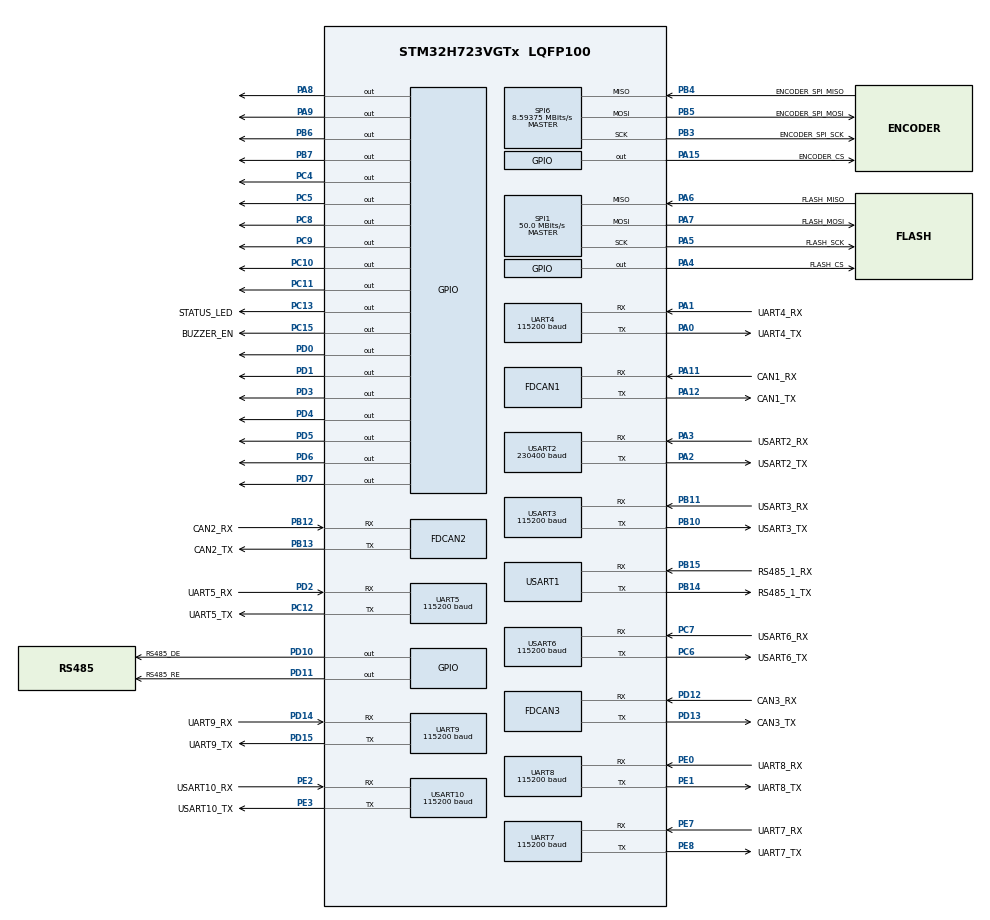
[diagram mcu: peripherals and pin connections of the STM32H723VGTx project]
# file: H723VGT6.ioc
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CORTEX_M7.CPU_DCache=Enabled
CORTEX_M7.CPU_ICache=Enabled
CORTEX_M7.default_mode_Activation=1
Dma.Request0=UART7_RX
Dma.Request1=UART7_TX
Dma.Request10=UART9_RX
Dma.Request2=USART1_RX
Dma.Request3=SPI1_RX
Dma.Request4=SPI1_TX
Dma.Request5=UART5_RX
Dma.Request6=USART6_RX
Dma.Request7=USART2_RX
Dma.Request8=UART8_RX
Dma.Request9=UART4_RX
Dma.SPI1_RX.3.Direction=DMA_PERIPH_TO_MEMORY
Dma.SPI1_RX.3.EventEnable=DISABLE
Dma.SPI1_RX.3.FIFOMode=DMA_FIFOMODE_DISABLE
Dma.SPI1_RX.3.Instance=DMA1_Stream6
Dma.SPI1_RX.3.MemDataAlignment=DMA_MDATAALIGN_BYTE
Dma.SPI1_RX.3.MemInc=DMA_MINC_ENABLE
Dma.SPI1_RX.3.Mode=DMA_NORMAL
Dma.SPI1_RX.3.PeriphDataAlignment=DMA_PDATAALIGN_BYTE
Dma.SPI1_RX.3.PeriphInc=DMA_PINC_DISABLE
Dma.SPI1_RX.3.Polarity=HAL_DMAMUX_REQ_GEN_RISING
Dma.SPI1_RX.3.Priority=DMA_PRIORITY_HIGH
Dma.SPI1_RX.3.RequestNumber=1
Dma.SPI1_RX.3.SignalID=NONE
Dma.SPI1_RX.3.SyncEnable=DISABLE
Dma.SPI1_RX.3.SyncPolarity=HAL_DMAMUX_SYNC_NO_EVENT
Dma.SPI1_RX.3.SyncRequestNumber=1
Dma.SPI1_RX.3.SyncSignalID=NONE
Dma.SPI1_TX.4.Direction=DMA_MEMORY_TO_PERIPH
Dma.SPI1_TX.4.EventEnable=DISABLE
Dma.SPI1_TX.4.FIFOMode=DMA_FIFOMODE_DISABLE
Dma.SPI1_TX.4.Instance=DMA1_Stream7
Dma.SPI1_TX.4.MemDataAlignment=DMA_MDATAALIGN_BYTE
Dma.SPI1_TX.4.MemInc=DMA_MINC_ENABLE
Dma.SPI1_TX.4.Mode=DMA_NORMAL
Dma.SPI1_TX.4.PeriphDataAlignment=DMA_PDATAALIGN_BYTE
Dma.SPI1_TX.4.PeriphInc=DMA_PINC_DISABLE
Dma.SPI1_TX.4.Polarity=HAL_DMAMUX_REQ_GEN_RISING
Dma.SPI1_TX.4.Priority=DMA_PRIORITY_HIGH
Dma.SPI1_TX.4.RequestNumber=1
Dma.SPI1_TX.4.SignalID=NONE
Dma.SPI1_TX.4.SyncEnable=DISABLE
Dma.SPI1_TX.4.SyncPolarity=HAL_DMAMUX_SYNC_NO_EVENT
Dma.SPI1_TX.4.SyncRequestNumber=1
Dma.SPI1_TX.4.SyncSignalID=NONE
Dma.UART4_RX.9.Direction=DMA_PERIPH_TO_MEMORY
Dma.UART4_RX.9.EventEnable=DISABLE
Dma.UART4_RX.9.FIFOMode=DMA_FIFOMODE_DISABLE
Dma.UART4_RX.9.Instance=DMA2_Stream3
Dma.UART4_RX.9.MemDataAlignment=DMA_MDATAALIGN_BYTE
Dma.UART4_RX.9.MemInc=DMA_MINC_ENABLE
Dma.UART4_RX.9.Mode=DMA_CIRCULAR
Dma.UART4_RX.9.PeriphDataAlignment=DMA_PDATAALIGN_BYTE
Dma.UART4_RX.9.PeriphInc=DMA_PINC_DISABLE
Dma.UART4_RX.9.Polarity=HAL_DMAMUX_REQ_GEN_RISING
Dma.UART4_RX.9.Priority=DMA_PRIORITY_VERY_HIGH
Dma.UART4_RX.9.RequestNumber=1
Dma.UART4_RX.9.SignalID=NONE
Dma.UART4_RX.9.SyncEnable=DISABLE
Dma.UART4_RX.9.SyncPolarity=HAL_DMAMUX_SYNC_NO_EVENT
Dma.UART4_RX.9.SyncRequestNumber=1
Dma.UART4_RX.9.SyncSignalID=NONE
Dma.UART5_RX.5.Direction=DMA_PERIPH_TO_MEMORY
Dma.UART5_RX.5.EventEnable=DISABLE
Dma.UART5_RX.5.FIFOMode=DMA_FIFOMODE_DISABLE
Dma.UART5_RX.5.Instance=DMA2_Stream0
Dma.UART5_RX.5.MemDataAlignment=DMA_MDATAALIGN_BYTE
Dma.UART5_RX.5.MemInc=DMA_MINC_ENABLE
Dma.UART5_RX.5.Mode=DMA_CIRCULAR
Dma.UART5_RX.5.PeriphDataAlignment=DMA_PDATAALIGN_BYTE
Dma.UART5_RX.5.PeriphInc=DMA_PINC_DISABLE
Dma.UART5_RX.5.Polarity=HAL_DMAMUX_REQ_GEN_RISING
Dma.UART5_RX.5.Priority=DMA_PRIORITY_VERY_HIGH
Dma.UART5_RX.5.RequestNumber=1
Dma.UART5_RX.5.SignalID=NONE
Dma.UART5_RX.5.SyncEnable=DISABLE
Dma.UART5_RX.5.SyncPolarity=HAL_DMAMUX_SYNC_NO_EVENT
Dma.UART5_RX.5.SyncRequestNumber=1
Dma.UART5_RX.5.SyncSignalID=NONE
Dma.UART7_RX.0.Direction=DMA_PERIPH_TO_MEMORY
Dma.UART7_RX.0.EventEnable=DISABLE
Dma.UART7_RX.0.FIFOMode=DMA_FIFOMODE_DISABLE
Dma.UART7_RX.0.Instance=DMA1_Stream0
Dma.UART7_RX.0.MemDataAlignment=DMA_MDATAALIGN_BYTE
Dma.UART7_RX.0.MemInc=DMA_MINC_ENABLE
Dma.UART7_RX.0.Mode=DMA_CIRCULAR
Dma.UART7_RX.0.PeriphDataAlignment=DMA_PDATAALIGN_BYTE
Dma.UART7_RX.0.PeriphInc=DMA_PINC_DISABLE
Dma.UART7_RX.0.Polarity=HAL_DMAMUX_REQ_GEN_RISING
Dma.UART7_RX.0.Priority=DMA_PRIORITY_VERY_HIGH
Dma.UART7_RX.0.RequestNumber=1
Dma.UART7_RX.0.SignalID=NONE
Dma.UART7_RX.0.SyncEnable=DISABLE
Dma.UART7_RX.0.SyncPolarity=HAL_DMAMUX_SYNC_NO_EVENT
Dma.UART7_RX.0.SyncRequestNumber=1
Dma.UART7_RX.0.SyncSignalID=NONE
Dma.UART7_TX.1.Direction=DMA_MEMORY_TO_PERIPH
Dma.UART7_TX.1.EventEnable=DISABLE
Dma.UART7_TX.1.FIFOMode=DMA_FIFOMODE_DISABLE
Dma.UART7_TX.1.Instance=DMA1_Stream1
Dma.UART7_TX.1.MemDataAlignment=DMA_MDATAALIGN_BYTE
Dma.UART7_TX.1.MemInc=DMA_MINC_ENABLE
Dma.UART7_TX.1.Mode=DMA_NORMAL
Dma.UART7_TX.1.PeriphDataAlignment=DMA_PDATAALIGN_BYTE
Dma.UART7_TX.1.PeriphInc=DMA_PINC_DISABLE
Dma.UART7_TX.1.Polarity=HAL_DMAMUX_REQ_GEN_RISING
Dma.UART7_TX.1.Priority=DMA_PRIORITY_HIGH
Dma.UART7_TX.1.RequestNumber=1
Dma.UART7_TX.1.SignalID=NONE
Dma.UART7_TX.1.SyncEnable=DISABLE
Dma.UART7_TX.1.SyncPolarity=HAL_DMAMUX_SYNC_NO_EVENT
Dma.UART7_TX.1.SyncRequestNumber=1
Dma.UART7_TX.1.SyncSignalID=NONE
Dma.UART8_RX.8.Direction=DMA_PERIPH_TO_MEMORY
Dma.UART8_RX.8.EventEnable=DISABLE
Dma.UART8_RX.8.FIFOMode=DMA_FIFOMODE_DISABLE
Dma.UART8_RX.8.Instance=DMA2_Stream2
Dma.UART8_RX.8.MemDataAlignment=DMA_MDATAALIGN_BYTE
Dma.UART8_RX.8.MemInc=DMA_MINC_ENABLE
Dma.UART8_RX.8.Mode=DMA_CIRCULAR
Dma.UART8_RX.8.PeriphDataAlignment=DMA_PDATAALIGN_BYTE
Dma.UART8_RX.8.PeriphInc=DMA_PINC_DISABLE
Dma.UART8_RX.8.Polarity=HAL_DMAMUX_REQ_GEN_RISING
Dma.UART8_RX.8.Priority=DMA_PRIORITY_VERY_HIGH
Dma.UART8_RX.8.RequestNumber=1
Dma.UART8_RX.8.SignalID=NONE
Dma.UART8_RX.8.SyncEnable=DISABLE
Dma.UART8_RX.8.SyncPolarity=HAL_DMAMUX_SYNC_NO_EVENT
Dma.UART8_RX.8.SyncRequestNumber=1
Dma.UART8_RX.8.SyncSignalID=NONE
Dma.UART9_RX.10.Direction=DMA_PERIPH_TO_MEMORY
Dma.UART9_RX.10.EventEnable=DISABLE
Dma.UART9_RX.10.FIFOMode=DMA_FIFOMODE_DISABLE
Dma.UART9_RX.10.Instance=DMA1_Stream4
Dma.UART9_RX.10.MemDataAlignment=DMA_MDATAALIGN_BYTE
Dma.UART9_RX.10.MemInc=DMA_MINC_ENABLE
Dma.UART9_RX.10.Mode=DMA_CIRCULAR
Dma.UART9_RX.10.PeriphDataAlignment=DMA_PDATAALIGN_BYTE
Dma.UART9_RX.10.PeriphInc=DMA_PINC_DISABLE
Dma.UART9_RX.10.Polarity=HAL_DMAMUX_REQ_GEN_RISING
Dma.UART9_RX.10.Priority=DMA_PRIORITY_LOW
Dma.UART9_RX.10.RequestNumber=1
Dma.UART9_RX.10.SignalID=NONE
Dma.UART9_RX.10.SyncEnable=DISABLE
Dma.UART9_RX.10.SyncPolarity=HAL_DMAMUX_SYNC_NO_EVENT
Dma.UART9_RX.10.SyncRequestNumber=1
Dma.UART9_RX.10.SyncSignalID=NONE
Dma.USART1_RX.2.Direction=DMA_PERIPH_TO_MEMORY
Dma.USART1_RX.2.EventEnable=DISABLE
Dma.USART1_RX.2.FIFOMode=DMA_FIFOMODE_DISABLE
Dma.USART1_RX.2.Instance=DMA1_Stream2
Dma.USART1_RX.2.MemDataAlignment=DMA_MDATAALIGN_BYTE
Dma.USART1_RX.2.MemInc=DMA_MINC_ENABLE
Dma.USART1_RX.2.Mode=DMA_CIRCULAR
Dma.USART1_RX.2.PeriphDataAlignment=DMA_PDATAALIGN_BYTE
Dma.USART1_RX.2.PeriphInc=DMA_PINC_DISABLE
Dma.USART1_RX.2.Polarity=HAL_DMAMUX_REQ_GEN_RISING
Dma.USART1_RX.2.Priority=DMA_PRIORITY_VERY_HIGH
Dma.USART1_RX.2.RequestNumber=1
Dma.USART1_RX.2.SignalID=NONE
Dma.USART1_RX.2.SyncEnable=DISABLE
Dma.USART1_RX.2.SyncPolarity=HAL_DMAMUX_SYNC_NO_EVENT
Dma.USART1_RX.2.SyncRequestNumber=1
Dma.USART1_RX.2.SyncSignalID=NONE
Dma.USART2_RX.7.Direction=DMA_PERIPH_TO_MEMORY
Dma.USART2_RX.7.EventEnable=DISABLE
Dma.USART2_RX.7.FIFOMode=DMA_FIFOMODE_DISABLE
Dma.USART2_RX.7.Instance=DMA1_Stream3
Dma.USART2_RX.7.MemDataAlignment=DMA_MDATAALIGN_BYTE
Dma.USART2_RX.7.MemInc=DMA_MINC_ENABLE
Dma.USART2_RX.7.Mode=DMA_CIRCULAR
Dma.USART2_RX.7.PeriphDataAlignment=DMA_PDATAALIGN_BYTE
Dma.USART2_RX.7.PeriphInc=DMA_PINC_DISABLE
Dma.USART2_RX.7.Polarity=HAL_DMAMUX_REQ_GEN_RISING
Dma.USART2_RX.7.Priority=DMA_PRIORITY_VERY_HIGH
Dma.USART2_RX.7.RequestNumber=1
Dma.USART2_RX.7.SignalID=NONE
Dma.USART2_RX.7.SyncEnable=DISABLE
Dma.USART2_RX.7.SyncPolarity=HAL_DMAMUX_SYNC_NO_EVENT
Dma.USART2_RX.7.SyncRequestNumber=1
Dma.USART2_RX.7.SyncSignalID=NONE
Dma.USART6_RX.6.Direction=DMA_PERIPH_TO_MEMORY
Dma.USART6_RX.6.EventEnable=DISABLE
Dma.USART6_RX.6.FIFOMode=DMA_FIFOMODE_DISABLE
Dma.USART6_RX.6.Instance=DMA2_Stream1
Dma.USART6_RX.6.MemDataAlignment=DMA_MDATAALIGN_BYTE
Dma.USART6_RX.6.MemInc=DMA_MINC_ENABLE
Dma.USART6_RX.6.Mode=DMA_CIRCULAR
Dma.USART6_RX.6.PeriphDataAlignment=DMA_PDATAALIGN_BYTE
Dma.USART6_RX.6.PeriphInc=DMA_PINC_DISABLE
Dma.USART6_RX.6.Polarity=HAL_DMAMUX_REQ_GEN_RISING
Dma.USART6_RX.6.Priority=DMA_PRIORITY_VERY_HIGH
Dma.USART6_RX.6.RequestNumber=1
Dma.USART6_RX.6.SignalID=NONE
Dma.USART6_RX.6.SyncEnable=DISABLE
Dma.USART6_RX.6.SyncPolarity=HAL_DMAMUX_SYNC_NO_EVENT
Dma.USART6_RX.6.SyncRequestNumber=1
Dma.USART6_RX.6.SyncSignalID=NONE
FDCAN1.AutoRetransmission=ENABLE
FDCAN1.CalculateBaudRateNominal=1000000
FDCAN1.CalculateTimeBitNominal=1000
FDCAN1.CalculateTimeQuantumNominal=50.0
FDCAN1.DataPrescaler=5
FDCAN1.DataSyncJumpWidth=5
FDCAN1.DataTimeSeg1=14
FDCAN1.DataTimeSeg2=5
FDCAN1.ExtFiltersNbr=1
FDCAN1.Mode=FDCAN_MODE_NORMAL
FDCAN1.NominalPrescaler=5
FDCAN1.NominalSyncJumpWidth=5
FDCAN1.NominalTimeSeg1=16
FDCAN1.NominalTimeSeg2=3
FDCAN1.RxFifo0ElmtsNbr=32
FDCAN1.RxFifo1ElmtsNbr=0
FDCAN1.StdFiltersNbr=1
FDCAN1.TxFifoQueueElmtsNbr=8
FDCAN2.AutoRetransmission=ENABLE
FDCAN2.CalculateBaudRateNominal=1000000
FDCAN2.CalculateTimeBitNominal=1000
FDCAN2.CalculateTimeQuantumNominal=50.0
FDCAN2.DataPrescaler=5
FDCAN2.DataSyncJumpWidth=5
FDCAN2.DataTimeSeg1=14
FDCAN2.DataTimeSeg2=5
FDCAN2.ExtFiltersNbr=1
FDCAN2.MessageRAMOffset=852
FDCAN2.Mode=FDCAN_MODE_NORMAL
FDCAN2.NominalPrescaler=5
FDCAN2.NominalSyncJumpWidth=5
FDCAN2.NominalTimeSeg1=14
FDCAN2.NominalTimeSeg2=5
FDCAN2.RxFifo0ElmtsNbr=32
FDCAN2.StdFiltersNbr=1
FDCAN2.TxFifoQueueElmtsNbr=8
FDCAN3.AutoRetransmission=ENABLE
FDCAN3.CalculateBaudRateNominal=1000000
FDCAN3.CalculateTimeBitNominal=1000
FDCAN3.CalculateTimeQuantumNominal=50.0
FDCAN3.DataPrescaler=5
FDCAN3.DataSyncJumpWidth=5
FDCAN3.DataTimeSeg1=14
FDCAN3.DataTimeSeg2=5
FDCAN3.ExtFiltersNbr=1
FDCAN3.MessageRAMOffset=1704
FDCAN3.Mode=FDCAN_MODE_NORMAL
FDCAN3.NominalPrescaler=5
FDCAN3.NominalSyncJumpWidth=5
FDCAN3.NominalTimeSeg1=14
FDCAN3.NominalTimeSeg2=5
FDCAN3.RxFifo0ElmtsNbr=32
FDCAN3.StdFiltersNbr=1
FDCAN3.TxFifoQueueElmtsNbr=8
<<<<<<< HEAD
FREERTOS.Tasks01=Status_Task,32,1024,Status_Task,As external,NULL,Dynamic,NULL,NULL;SuctionCup_Task,24,512,SuctionCup_Task,As external,NULL,Dynamic,NULL,NULL;Arm_Task,24,512,Arm_Task,As external,NULL,Dynamic,NULL,NULL;Chassis_Task,16,256,Chassis_Task_,As external,NULL,Dynamic,NULL,NULL
=======
FREERTOS.Tasks01=Status_Task,32,1024,Status_Task,As external,NULL,Dynamic,NULL,NULL;SuctionCup_Task,24,512,SuctionCup_Task,As external,NULL,Dynamic,NULL,NULL;Arm_Task,24,512,Arm_Task,As external,NULL,Dynamic,NULL,NULL
>>>>>>> c1f3984123493276c22fa7685c0e10887a5564d8
FREERTOS.configCHECK_FOR_STACK_OVERFLOW=2
FREERTOS.configENABLE_FPU=1
FREERTOS.configTOTAL_HEAP_SIZE=65536
Mcu.Family=STM32H7
Mcu.Name=STM32H723VGTx
Mcu.Package=LQFP100
NVIC.DMA1_Stream0_IRQn=true\:5\:0\:false\:false\:true\:true\:true\:true\:true
NVIC.DMA1_Stream1_IRQn=true\:5\:0\:false\:false\:true\:true\:true\:true\:true
NVIC.DMA1_Stream2_IRQn=true\:5\:0\:false\:false\:true\:true\:true\:true\:true
NVIC.DMA1_Stream3_IRQn=true\:5\:0\:false\:false\:true\:true\:true\:true\:true
NVIC.DMA1_Stream4_IRQn=true\:5\:0\:false\:false\:true\:true\:false\:true\:true
NVIC.DMA1_Stream6_IRQn=true\:5\:0\:false\:false\:true\:true\:true\:true\:true
NVIC.DMA1_Stream7_IRQn=true\:5\:0\:false\:false\:true\:true\:true\:true\:true
NVIC.DMA2_Stream0_IRQn=true\:5\:0\:false\:false\:true\:true\:true\:true\:true
NVIC.DMA2_Stream1_IRQn=true\:5\:0\:false\:false\:true\:true\:true\:true\:true
NVIC.DMA2_Stream2_IRQn=true\:5\:0\:false\:false\:true\:true\:true\:true\:true
NVIC.DMA2_Stream3_IRQn=true\:5\:0\:false\:false\:true\:true\:true\:true\:true
NVIC.FDCAN1_IT0_IRQn=true\:5\:0\:false\:false\:true\:true\:true\:true\:true
NVIC.FDCAN2_IT0_IRQn=true\:5\:0\:false\:false\:true\:true\:true\:true\:true
NVIC.FDCAN3_IT0_IRQn=true\:5\:0\:false\:false\:true\:true\:true\:true\:true
NVIC.PriorityGroup=NVIC_PRIORITYGROUP_4
NVIC.SPI1_IRQn=true\:5\:0\:false\:false\:true\:true\:true\:true\:true
NVIC.TIM6_DAC_IRQn=true\:15\:0\:false\:false\:true\:false\:false\:true\:true
NVIC.TimeBase=TIM6_DAC_IRQn
NVIC.TimeBaseIP=TIM6
NVIC.UART4_IRQn=true\:5\:0\:false\:false\:true\:true\:true\:true\:true
NVIC.UART5_IRQn=true\:5\:0\:false\:false\:true\:true\:true\:true\:true
NVIC.UART7_IRQn=true\:5\:0\:false\:false\:true\:true\:true\:true\:true
NVIC.UART8_IRQn=true\:5\:0\:false\:false\:true\:true\:true\:true\:true
NVIC.UART9_IRQn=true\:5\:0\:false\:false\:true\:true\:true\:true\:true
NVIC.USART10_IRQn=true\:5\:0\:false\:false\:true\:true\:true\:true\:true
NVIC.USART1_IRQn=true\:5\:0\:false\:false\:true\:true\:true\:true\:true
NVIC.USART2_IRQn=true\:5\:0\:false\:false\:true\:true\:true\:true\:true
NVIC.USART3_IRQn=true\:5\:0\:false\:false\:true\:true\:true\:true\:true
NVIC.USART6_IRQn=true\:5\:0\:false\:false\:true\:true\:true\:true\:true
PA0.GPIO_Label=UART4_TX
PA0.GPIO_Speed=GPIO_SPEED_FREQ_VERY_HIGH
PA0.Mode=Asynchronous
PA0.Signal=UART4_TX
PA1.GPIO_Label=UART4_RX
PA1.GPIO_Speed=GPIO_SPEED_FREQ_VERY_HIGH
PA1.Mode=Asynchronous
PA1.Signal=UART4_RX
PA11.GPIO_Label=CAN1_RX
PA11.GPIO_Speed=GPIO_SPEED_FREQ_VERY_HIGH
PA11.Mode=FDCAN_Activate
PA11.Signal=FDCAN1_RX
PA12.GPIO_Label=CAN1_TX
PA12.GPIO_Speed=GPIO_SPEED_FREQ_VERY_HIGH
PA12.Mode=FDCAN_Activate
PA12.Signal=FDCAN1_TX
PA13(JTMS/SWDIO).Mode=Serial_Wire
PA13(JTMS/SWDIO).Signal=DEBUG_JTMS-SWDIO
PA14(JTCK/SWCLK).Mode=Serial_Wire
PA14(JTCK/SWCLK).Signal=DEBUG_JTCK-SWCLK
PA15(JTDI).GPIO_Label=ENCODER_CS
PA15(JTDI).GPIO_Speed=GPIO_SPEED_FREQ_VERY_HIGH
PA15(JTDI).PinState=GPIO_PIN_SET
PA15(JTDI).Signal=GPIO_Output
PA2.GPIO_Label=USART2_TX
PA2.GPIO_Speed=GPIO_SPEED_FREQ_VERY_HIGH
PA2.Mode=Asynchronous
PA2.Signal=USART2_TX
PA3.GPIO_Label=USART2_RX
PA3.GPIO_Speed=GPIO_SPEED_FREQ_VERY_HIGH
PA3.Mode=Asynchronous
PA3.Signal=USART2_RX
PA4.GPIO_Label=FLASH_CS
PA4.GPIO_Speed=GPIO_SPEED_FREQ_VERY_HIGH
PA4.PinState=GPIO_PIN_SET
PA4.Signal=GPIO_Output
PA5.GPIO_Label=FLASH_SCK
PA5.GPIO_Speed=GPIO_SPEED_FREQ_VERY_HIGH
PA5.Mode=Full_Duplex_Master
PA5.Signal=SPI1_SCK
PA6.GPIO_Label=FLASH_MISO
PA6.GPIO_Speed=GPIO_SPEED_FREQ_VERY_HIGH
PA6.Mode=Full_Duplex_Master
PA6.Signal=SPI1_MISO
PA7.GPIO_Label=FLASH_MOSI
PA7.GPIO_Speed=GPIO_SPEED_FREQ_VERY_HIGH
PA7.Mode=Full_Duplex_Master
PA7.Signal=SPI1_MOSI
PA8.Signal=GPIO_Output
PA9.Signal=GPIO_Output
PB10.GPIO_Label=USART3_TX
PB10.GPIO_Speed=GPIO_SPEED_FREQ_VERY_HIGH
PB10.Mode=Asynchronous
PB10.Signal=USART3_TX
PB11.GPIO_Label=USART3_RX
PB11.GPIO_Speed=GPIO_SPEED_FREQ_VERY_HIGH
PB11.Mode=Asynchronous
PB11.Signal=USART3_RX
PB12.GPIO_Label=CAN2_RX
PB12.GPIO_Speed=GPIO_SPEED_FREQ_VERY_HIGH
PB12.Mode=FDCAN_Activate
PB12.Signal=FDCAN2_RX
PB13.GPIO_Label=CAN2_TX
PB13.GPIO_Speed=GPIO_SPEED_FREQ_VERY_HIGH
PB13.Mode=FDCAN_Activate
PB13.Signal=FDCAN2_TX
PB14.GPIO_Label=RS485_1_TX
PB14.GPIO_Speed=GPIO_SPEED_FREQ_VERY_HIGH
PB14.Mode=Asynchronous
PB14.Signal=USART1_TX
PB15.GPIO_Label=RS485_1_RX
PB15.GPIO_Speed=GPIO_SPEED_FREQ_VERY_HIGH
PB15.Mode=Asynchronous
PB15.Signal=USART1_RX
PB3(JTDO/TRACESWO).GPIO_Label=ENCODER_SPI_SCK
PB3(JTDO/TRACESWO).GPIO_Speed=GPIO_SPEED_FREQ_VERY_HIGH
PB3(JTDO/TRACESWO).Mode=Full_Duplex_Master
PB3(JTDO/TRACESWO).Signal=SPI6_SCK
PB4(NJTRST).GPIO_Label=ENCODER_SPI_MISO
PB4(NJTRST).GPIO_Speed=GPIO_SPEED_FREQ_VERY_HIGH
PB4(NJTRST).Mode=Full_Duplex_Master
PB4(NJTRST).Signal=SPI6_MISO
PB5.GPIO_Label=ENCODER_SPI_MOSI
PB5.GPIO_Speed=GPIO_SPEED_FREQ_VERY_HIGH
PB5.Mode=Full_Duplex_Master
PB5.Signal=SPI6_MOSI
PB6.Signal=GPIO_Output
PB7.Signal=GPIO_Output
PC10.Signal=GPIO_Output
PC11.Signal=GPIO_Output
PC12.GPIO_Label=UART5_TX
PC12.GPIO_Speed=GPIO_SPEED_FREQ_VERY_HIGH
PC12.Mode=Asynchronous
PC12.Signal=UART5_TX
PC13.GPIO_Label=STATUS_LED
PC13.GPIO_Speed=GPIO_SPEED_FREQ_LOW
PC13.PinState=GPIO_PIN_RESET
PC13.Signal=GPIO_Output
PC15-OSC32_OUT.GPIO_Label=BUZZER_EN
PC15-OSC32_OUT.GPIO_Speed=GPIO_SPEED_FREQ_LOW
PC15-OSC32_OUT.PinState=GPIO_PIN_RESET
PC15-OSC32_OUT.Signal=GPIO_Output
PC4.GPIO_PuPd=GPIO_PULLUP
PC4.PinState=GPIO_PIN_SET
PC4.Signal=GPIO_Output
PC5.GPIO_PuPd=GPIO_PULLUP
PC5.PinState=GPIO_PIN_SET
PC5.Signal=GPIO_Output
PC6.GPIO_Label=USART6_TX
PC6.GPIO_Speed=GPIO_SPEED_FREQ_VERY_HIGH
PC6.Mode=Asynchronous
PC6.Signal=USART6_TX
PC7.GPIO_Label=USART6_RX
PC7.GPIO_Speed=GPIO_SPEED_FREQ_VERY_HIGH
PC7.Mode=Asynchronous
PC7.Signal=USART6_RX
PC8.Signal=GPIO_Output
PC9.Signal=GPIO_Output
PD0.Signal=GPIO_Output
PD1.Signal=GPIO_Output
PD10.GPIO_Label=RS485_DE
PD10.GPIO_Speed=GPIO_SPEED_FREQ_LOW
PD10.PinState=GPIO_PIN_RESET
PD10.Signal=GPIO_Output
PD11.GPIO_Label=RS485_RE
PD11.GPIO_Speed=GPIO_SPEED_FREQ_LOW
PD11.PinState=GPIO_PIN_RESET
PD11.Signal=GPIO_Output
PD12.GPIO_Label=CAN3_RX
PD12.GPIO_Speed=GPIO_SPEED_FREQ_VERY_HIGH
PD12.Mode=FDCAN_Activate
PD12.Signal=FDCAN3_RX
PD13.GPIO_Label=CAN3_TX
PD13.GPIO_Speed=GPIO_SPEED_FREQ_VERY_HIGH
PD13.Mode=FDCAN_Activate
PD13.Signal=FDCAN3_TX
PD14.GPIO_Label=UART9_RX
PD14.GPIO_Speed=GPIO_SPEED_FREQ_VERY_HIGH
PD14.Mode=Asynchronous
PD14.Signal=UART9_RX
PD15.GPIO_Label=UART9_TX
PD15.GPIO_Speed=GPIO_SPEED_FREQ_VERY_HIGH
PD15.Mode=Asynchronous
PD15.Signal=UART9_TX
PD2.GPIO_Label=UART5_RX
PD2.GPIO_Speed=GPIO_SPEED_FREQ_VERY_HIGH
PD2.Mode=Asynchronous
PD2.Signal=UART5_RX
PD3.Signal=GPIO_Output
PD4.Signal=GPIO_Output
PD5.Signal=GPIO_Output
PD6.Signal=GPIO_Output
PD7.Signal=GPIO_Output
PE0.GPIO_Label=UART8_RX
PE0.GPIO_Speed=GPIO_SPEED_FREQ_VERY_HIGH
PE0.Mode=Asynchronous
PE0.Signal=UART8_RX
PE1.GPIO_Label=UART8_TX
PE1.GPIO_Speed=GPIO_SPEED_FREQ_VERY_HIGH
PE1.Mode=Asynchronous
PE1.Signal=UART8_TX
PE2.GPIO_Label=USART10_RX
PE2.GPIO_Speed=GPIO_SPEED_FREQ_VERY_HIGH
PE2.Mode=Asynchronous
PE2.Signal=USART10_RX
PE3.GPIO_Label=USART10_TX
PE3.GPIO_Speed=GPIO_SPEED_FREQ_VERY_HIGH
PE3.Mode=Asynchronous
PE3.Signal=USART10_TX
PE7.GPIO_Label=UART7_RX
PE7.GPIO_Speed=GPIO_SPEED_FREQ_VERY_HIGH
PE7.Mode=Asynchronous
PE7.Signal=UART7_RX
PE8.GPIO_Label=UART7_TX
PE8.GPIO_Speed=GPIO_SPEED_FREQ_VERY_HIGH
PE8.Mode=Asynchronous
PE8.Signal=UART7_TX
PH0-OSC_IN.Mode=HSE-External-Oscillator
PH0-OSC_IN.Signal=RCC_OSC_IN
PH1-OSC_OUT.Mode=HSE-External-Oscillator
PH1-OSC_OUT.Signal=RCC_OSC_OUT
ProjectManager.HeapSize=0x800
ProjectManager.StackSize=0x1000
ProjectManager.TargetToolchain=MDK-ARM V5.32
RCC.ADCFreq_Value=100000000
RCC.APB1Freq_Value=137500000
RCC.APB2Freq_Value=137500000
RCC.APB3Freq_Value=137500000
RCC.APB4Freq_Value=137500000
RCC.CortexFreq_Value=550000000
RCC.D1PPRE=RCC_APB3_DIV2
RCC.D2PPRE1=RCC_APB1_DIV2
RCC.D2PPRE2=RCC_APB2_DIV2
RCC.D3PPRE=RCC_APB4_DIV2
RCC.DIVM1=5
RCC.DIVM2=5
RCC.DIVN1=110
RCC.DIVN2=40
RCC.DIVP1=1
RCC.FDCANCLockSelection=RCC_FDCANCLKSOURCE_PLL2
RCC.HCLKFreq_Value=275000000
RCC.HPRE=RCC_HCLK_DIV2
RCC.HSE_VALUE=25000000
RCC.PLL2FRACN=0
RCC.PLL3FRACN=0
RCC.PLLFRACN=0
RCC.PLLSourceVirtual=RCC_PLLSOURCE_HSE
RCC.SPI123CLockSelection=RCC_SPI123CLKSOURCE_PLL2
RCC.SYSCLKFreq_VALUE=550000000
RCC.SYSCLKSource=RCC_SYSCLKSOURCE_PLLCLK
RCC.USART16CLockSelection=RCC_USART16910CLKSOURCE_PLL2
RCC.USART234578CLockSelection=RCC_USART234578CLKSOURCE_PLL2
RCC.USBFreq_Value=275000000
SPI1.CalculateBaudRate=50.0 MBits/s
SPI1.DataSize=SPI_DATASIZE_8BIT
SPI1.Direction=SPI_DIRECTION_2LINES
SPI1.Mode=SPI_MODE_MASTER
SPI1.VirtualType=VM_MASTER
SPI6.BaudRatePrescaler=SPI_BAUDRATEPRESCALER_16
SPI6.CalculateBaudRate=8.59375 MBits/s
SPI6.DataSize=SPI_DATASIZE_8BIT
SPI6.Direction=SPI_DIRECTION_2LINES
SPI6.Mode=SPI_MODE_MASTER
SPI6.VirtualType=VM_MASTER
UART4.BaudRate=115200
UART4.VirtualMode-Asynchronous=VM_ASYNC
UART5.BaudRate=115200
UART5.VirtualMode-Asynchronous=VM_ASYNC
UART7.BaudRate=115200
UART7.VirtualMode-Asynchronous=VM_ASYNC
UART8.BaudRate=115200
UART8.VirtualMode-Asynchronous=VM_ASYNC
UART9.BaudRate=115200
UART9.VirtualMode-Asynchronous=VM_ASYNC
USART1.VirtualMode-Asynchronous=VM_ASYNC
USART10.BaudRate=115200
USART10.VirtualMode=VM_ASYNC
USART10.VirtualMode-Asynchronous=VM_ASYNC
USART2.BaudRate=230400
USART2.VirtualMode-Asynchronous=VM_ASYNC
USART3.BaudRate=115200
USART3.VirtualMode-Asynchronous=VM_ASYNC
USART6.BaudRate=115200
USART6.VirtualMode=VM_ASYNC
USART6.VirtualMode-Asynchronous=VM_ASYNC
VP_FREERTOS_VS_CMSIS_V2.Mode=CMSIS_V2
VP_MEMORYMAP_VS_MEMORYMAP.Mode=CurAppReg
VP_SYS_VS_tim6.Mode=TIM6
board=custom

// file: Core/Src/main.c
/* USER CODE BEGIN Header */
/**
  ******************************************************************************
  * @file           : main.c
  * @brief          : Main program body
  ******************************************************************************
  * @attention
  *
  * Copyright (c) 2026 STMicroelectronics.
  * All rights reserved.
  *
  * This software is licensed under terms that can be found in the LICENSE file
  * in the root directory of this software component.
  * If no LICENSE file comes with this software, it is provided AS-IS.
  *
  ******************************************************************************
  */
/* USER CODE END Header */
#include "main.h"
#include "FreeRTOS.h"
#include "cmsis_os2.h"
#include "dma.h"
#include "fdcan.h"
#include "spi.h"
#include "usart.h"
#include "gpio.h"

/* USER CODE BEGIN Includes */
/* BR: no TR down mechanism. */
#include "my_main.h"
/* USER CODE END Includes */

void SystemClock_Config(void);
void PeriphCommonClock_Config(void);
static void MPU_Config(void);
void MX_FREERTOS_Init(void);

int main(void)
{

  /* MPU Configuration--------------------------------------------------------*/
  MPU_Config();

  /* Enable the CPU Cache */

  /* Enable I-Cache---------------------------------------------------------*/
  SCB_EnableICache();

  /* Enable D-Cache---------------------------------------------------------*/
  SCB_EnableDCache();

  /* MCU Configuration--------------------------------------------------------*/

  /* Reset of all peripherals, Initializes the Flash interface and the Systick. */
  HAL_Init();

  /* Configure the system clock */
  SystemClock_Config();

  /* Configure the peripherals common clocks */
  PeriphCommonClock_Config();

  /* Initialize all configured peripherals */
  MX_GPIO_Init();
  MX_DMA_Init();
  MX_FDCAN1_Init();
  MX_FDCAN2_Init();
  MX_FDCAN3_Init();
  MX_SPI1_Init();
  MX_SPI6_Init();
  MX_UART4_Init();
  MX_USART1_UART_Init();
  MX_USART2_UART_Init();
  MX_UART5_Init();
  MX_UART7_Init();
  MX_UART8_Init();
  MX_UART9_Init();
  MX_USART3_UART_Init();
  MX_USART6_UART_Init();
  MX_USART10_UART_Init();
  /* USER CODE BEGIN 2 */
  /* 外设初始化完成后再次将 PC4、PC5 置为高电平，与 gpio.c 中的初始电平保持一致。
     保留在 USER CODE 2 区域内，以便 CubeMX 重新生成代码时保留此设置。 */
  HAL_GPIO_WritePin(GPIOC, GPIO_PIN_4, GPIO_PIN_SET);
  HAL_GPIO_WritePin(GPIOC, GPIO_PIN_5, GPIO_PIN_SET);
  /* Flash commands use 8-bit SPI frames. */
  hspi1.Init.DataSize = SPI_DATASIZE_8BIT;
  (void)HAL_SPI_Init(&hspi1);

  My_Init();

  /* USER CODE END 2 */

  /* Init scheduler */
  osKernelInitialize();  /* Call init function for freertos objects (in cmsis_os2.c) */
  MX_FREERTOS_Init();

  /* Start scheduler */
  osKernelStart();

  /* We should never get here as control is now taken by the scheduler */

  /* Infinite loop */
  while (1)
  {

  }
}

void SystemClock_Config(void)
{
  RCC_OscInitTypeDef RCC_OscInitStruct = {0};
  RCC_ClkInitTypeDef RCC_ClkInitStruct = {0};

  /** Supply configuration update enable
  */
  HAL_PWREx_ConfigSupply(PWR_LDO_SUPPLY);

  /** Configure the main internal regulator output voltage
  */
  __HAL_PWR_VOLTAGESCALING_CONFIG(PWR_REGULATOR_VOLTAGE_SCALE0);

  while(!__HAL_PWR_GET_FLAG(PWR_FLAG_VOSRDY)) {}

  /** Initializes the RCC Oscillators according to the specified parameters
  * in the RCC_OscInitTypeDef structure.
  */
  RCC_OscInitStruct.OscillatorType = RCC_OSCILLATORTYPE_HSE;
  RCC_OscInitStruct.HSEState = RCC_HSE_ON;
  RCC_OscInitStruct.PLL.PLLState = RCC_PLL_ON;
  RCC_OscInitStruct.PLL.PLLSource = RCC_PLLSOURCE_HSE;
  RCC_OscInitStruct.PLL.PLLM = 5;
  RCC_OscInitStruct.PLL.PLLN = 110;
  RCC_OscInitStruct.PLL.PLLP = 1;
  RCC_OscInitStruct.PLL.PLLQ = 2;
  RCC_OscInitStruct.PLL.PLLR = 2;
  RCC_OscInitStruct.PLL.PLLRGE = RCC_PLL1VCIRANGE_2;
  RCC_OscInitStruct.PLL.PLLVCOSEL = RCC_PLL1VCOWIDE;
  RCC_OscInitStruct.PLL.PLLFRACN = 0;
  if (HAL_RCC_OscConfig(&RCC_OscInitStruct) != HAL_OK)
  {
    Error_Handler();
  }

  /** Initializes the CPU, AHB and APB buses clocks
  */
  RCC_ClkInitStruct.ClockType = RCC_CLOCKTYPE_HCLK|RCC_CLOCKTYPE_SYSCLK
                              |RCC_CLOCKTYPE_PCLK1|RCC_CLOCKTYPE_PCLK2
                              |RCC_CLOCKTYPE_D3PCLK1|RCC_CLOCKTYPE_D1PCLK1;
  RCC_ClkInitStruct.SYSCLKSource = RCC_SYSCLKSOURCE_PLLCLK;
  RCC_ClkInitStruct.SYSCLKDivider = RCC_SYSCLK_DIV1;
  RCC_ClkInitStruct.AHBCLKDivider = RCC_HCLK_DIV2;
  RCC_ClkInitStruct.APB3CLKDivider = RCC_APB3_DIV2;
  RCC_ClkInitStruct.APB1CLKDivider = RCC_APB1_DIV2;
  RCC_ClkInitStruct.APB2CLKDivider = RCC_APB2_DIV2;
  RCC_ClkInitStruct.APB4CLKDivider = RCC_APB4_DIV2;

  if (HAL_RCC_ClockConfig(&RCC_ClkInitStruct, FLASH_LATENCY_3) != HAL_OK)
  {
    Error_Handler();
  }
}

void PeriphCommonClock_Config(void)
{
  RCC_PeriphCLKInitTypeDef PeriphClkInitStruct = {0};

  /** Initializes the peripherals clock
  */
  PeriphClkInitStruct.PeriphClockSelection = RCC_PERIPHCLK_SPI1|RCC_PERIPHCLK_UART5
                              |RCC_PERIPHCLK_UART8|RCC_PERIPHCLK_FDCAN
                              |RCC_PERIPHCLK_USART1|RCC_PERIPHCLK_USART6
                              |RCC_PERIPHCLK_USART10|RCC_PERIPHCLK_UART9
                              |RCC_PERIPHCLK_UART7|RCC_PERIPHCLK_UART4
                              |RCC_PERIPHCLK_USART2|RCC_PERIPHCLK_USART3;
  PeriphClkInitStruct.PLL2.PLL2M = 5;
  PeriphClkInitStruct.PLL2.PLL2N = 40;
  PeriphClkInitStruct.PLL2.PLL2P = 2;
  PeriphClkInitStruct.PLL2.PLL2Q = 2;
  PeriphClkInitStruct.PLL2.PLL2R = 2;
  PeriphClkInitStruct.PLL2.PLL2RGE = RCC_PLL2VCIRANGE_2;
  PeriphClkInitStruct.PLL2.PLL2VCOSEL = RCC_PLL2VCOWIDE;
  PeriphClkInitStruct.PLL2.PLL2FRACN = 0;
  PeriphClkInitStruct.Spi123ClockSelection = RCC_SPI123CLKSOURCE_PLL2;
  PeriphClkInitStruct.FdcanClockSelection = RCC_FDCANCLKSOURCE_PLL2;
  PeriphClkInitStruct.Usart234578ClockSelection = RCC_USART234578CLKSOURCE_PLL2;
  PeriphClkInitStruct.Usart16ClockSelection = RCC_USART16910CLKSOURCE_PLL2;
  if (HAL_RCCEx_PeriphCLKConfig(&PeriphClkInitStruct) != HAL_OK)
  {
    Error_Handler();
  }
}

 /* MPU Configuration */

void MPU_Config(void)
{
  MPU_Region_InitTypeDef MPU_InitStruct = {0};

  /* Disables the MPU */
  HAL_MPU_Disable();

  /** Initializes and configures the Region and the memory to be protected
  */
  MPU_InitStruct.Enable = MPU_REGION_ENABLE;
  MPU_InitStruct.Number = MPU_REGION_NUMBER0;
  MPU_InitStruct.BaseAddress = 0x0;
  MPU_InitStruct.Size = MPU_REGION_SIZE_4GB;
  MPU_InitStruct.SubRegionDisable = 0x87;
  MPU_InitStruct.TypeExtField = MPU_TEX_LEVEL0;
  MPU_InitStruct.AccessPermission = MPU_REGION_NO_ACCESS;
  MPU_InitStruct.DisableExec = MPU_INSTRUCTION_ACCESS_DISABLE;
  MPU_InitStruct.IsShareable = MPU_ACCESS_SHAREABLE;
  MPU_InitStruct.IsCacheable = MPU_ACCESS_NOT_CACHEABLE;
  MPU_InitStruct.IsBufferable = MPU_ACCESS_NOT_BUFFERABLE;

  HAL_MPU_ConfigRegion(&MPU_InitStruct);
  /* Enables the MPU */
  HAL_MPU_Enable(MPU_PRIVILEGED_DEFAULT);

}

void HAL_TIM_PeriodElapsedCallback(TIM_HandleTypeDef *htim)
{
  if (htim->Instance == TIM6)
  {
    HAL_IncTick();
  }
}

void Error_Handler(void)
{
  __disable_irq();
  while (1)
  {
  }
}

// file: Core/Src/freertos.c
/* USER CODE BEGIN Header */
/* CubeMX RTOS entry point with the user task setup kept in this file. */
/* USER CODE END Header */

#include "FreeRTOS.h"
#include "task.h"
#include "main.h"
#include "FreeRTOS.h"
#include "cmsis_os2.h"

/* USER CODE BEGIN Includes */
#include "my_main.h"

/* USER CODE END Includes */

/* Definitions for Status_Task */
osThreadId_t Status_TaskHandle;
const osThreadAttr_t Status_Task_attributes = {
  .name = "Status_Task",
  .stack_size = 1024 * 4,
  .priority = (osPriority_t) osPriorityAboveNormal,
};
/* Definitions for SuctionCup_Task */
osThreadId_t SuctionCup_TaskHandle;
const osThreadAttr_t SuctionCup_Task_attributes = {
  .name = "SuctionCup_Task",
  .stack_size = 512 * 4,
  .priority = (osPriority_t) osPriorityNormal,
};
/* Definitions for Arm_Task */
osThreadId_t Arm_TaskHandle;
const osThreadAttr_t Arm_Task_attributes = {
  .name = "Arm_Task",
  .stack_size = 512 * 4,
  .priority = (osPriority_t) osPriorityNormal,
};
/* Definitions for Chassis_Task */
osThreadId_t Chassis_TaskHandle;
const osThreadAttr_t Chassis_Task_attributes = {
  .name = "Chassis_Task",
  .stack_size = 256 * 4,
  .priority = (osPriority_t) osPriorityBelowNormal,
};

extern void Status_Task(void *argument);
extern void SuctionCup_Task(void *argument);
extern void Arm_Task(void *argument);
extern void Chassis_Task_(void *argument);

void MX_FREERTOS_Init(void); /* (MISRA C 2004 rule 8.1) */

/* Hook prototypes */
void vApplicationStackOverflowHook(xTaskHandle xTask, char *pcTaskName);

/* USER CODE BEGIN 4 */
void vApplicationStackOverflowHook(TaskHandle_t xTask, char *pcTaskName)
{
   (void)xTask;
   (void)pcTaskName;
   /* Run time stack overflow checking is performed if
   configCHECK_FOR_STACK_OVERFLOW is defined to 1 or 2. This hook function is
   called if a stack overflow is detected. */
}
/* USER CODE END 4 */

void MX_FREERTOS_Init(void) {

  /* Create the thread(s) */
  /* creation of Status_Task */
  Status_TaskHandle = osThreadNew(Status_Task, NULL, &Status_Task_attributes);

  /* creation of SuctionCup_Task */
  SuctionCup_TaskHandle = osThreadNew(SuctionCup_Task, NULL, &SuctionCup_Task_attributes);

  /* creation of Arm_Task */
  Arm_TaskHandle = osThreadNew(Arm_Task, NULL, &Arm_Task_attributes);

  /* creation of Chassis_Task */
  Chassis_TaskHandle = osThreadNew(Chassis_Task_, NULL, &Chassis_Task_attributes);

  /* USER CODE BEGIN RTOS_THREADS */
  My_RtosInit();
  Queue_Init();

  /* USER CODE END RTOS_THREADS */

}

__weak void Status_Task(void *argument)
{
  for(;;)
  {
    osDelay(1);
  }
}
